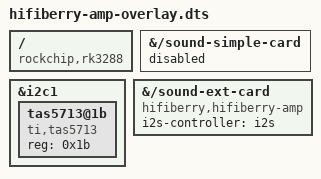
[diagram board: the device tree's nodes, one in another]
/dts-v1/;
/plugin/;

/ {
	compatible = "rockchip,rk3288";

	fragment@0 {
		target-path ="/sound-simple-card";
		__overlay__ {
			status = "disabled";
		};
	};

	fragment@1 {
		target = <&i2c1>;
		__overlay__ {
			#address-cells = <1>;
			#size-cells = <0>;
			status = "okay";

			tas5713@1b {
				#sound-dai-cells = <0>;
				compatible = "ti,tas5713";
				reg = <0x1b>;
				status = "okay";
			};
		};
	};

	fragment@2 {
		target-path = "/sound-ext-card";
		__overlay__ {
			compatible = "hifiberry,hifiberry-amp";
			i2s-controller = <&i2s>;
			status = "okay";
		};
	};
};
